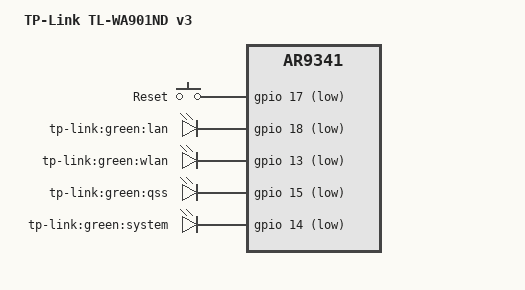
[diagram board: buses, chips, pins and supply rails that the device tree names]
// SPDX-License-Identifier: GPL-2.0-or-later OR MIT

#include "ar9341_tplink_tl-wa.dtsi"

/ {
	model = "TP-Link TL-WA901ND v3";
	compatible = "tplink,tl-wa901nd-v3", "qca,ar9341";

	aliases {
		led-boot = &led_system;
		led-failsafe = &led_system;
		led-running = &led_system;
		led-upgrade = &led_system;
	};

	keys {
		compatible = "gpio-keys";

		reset {
			label = "Reset";
			linux,code = <KEY_RESTART>;
			gpios = <&gpio 17 GPIO_ACTIVE_LOW>;
			debounce-interval = <60>;
		};
	};

	leds {
		compatible = "gpio-leds";

		lan {
			label = "tp-link:green:lan";
			gpios = <&gpio 18 GPIO_ACTIVE_LOW>;
		};

		wlan {
			label = "tp-link:green:wlan";
			gpios = <&gpio 13 GPIO_ACTIVE_LOW>;
			linux,default-trigger = "phy0tpt";
		};

		qss {
			label = "tp-link:green:qss";
			gpios = <&gpio 15 GPIO_ACTIVE_LOW>;
		};

		led_system: system {
			label = "tp-link:green:system";
			gpios = <&gpio 14 GPIO_ACTIVE_LOW>;
		};
	};
};
